# daric register map
Vendor: cramium
Registers are 32-bit, read-write, reset 0x0 unless marked. A register's access mark holds for its fields unless they carry their own. Offsets are from the block's base; [hi:lo] are bit positions; {n}, {i} and the like mark numbered series.

## IOX
Base 0x5012F000
{0x0+4i} SFR_AFSEL_CRAFSEL{i} (i=0..11) — See file:///F:/code/cram-soc/soc_oss/rtl/ifsub/iox_v0.3.sv
  [15:0] crafsel{i} — crafsel read/write control register
{0x100+4i} SFR_INTCR_CRINT{i} (i=0..7) — See file:///F:/code/cram-soc/soc_oss/rtl/ifsub/iox_v0.3.sv
  [9:0] crint{i} — crint read/write control register
0x120 SFR_INTFR — See file:///F:/code/cram-soc/soc_oss/rtl/ifsub/iox_v0.3.sv
  [7:0] frint — frint flag register. `1` means event happened, write back `1` in respective bit position to clear the flag
{0x130+4i} SFR_GPIOOUT_CRGO{i} (i=0..5) — See file:///F:/code/cram-soc/soc_oss/rtl/ifsub/iox_v0.3.sv
  [15:0] crgo{i} — crgo read/write control register
{0x148+4i} SFR_GPIOOE_CRGOE{i} (i=0..5) — See file:///F:/code/cram-soc/soc_oss/rtl/ifsub/iox_v0.3.sv
  [15:0] crgoe{i} — crgoe read/write control register
{0x160+4i} SFR_GPIOPU_CRGPU{i} (i=0..5) — See file:///F:/code/cram-soc/soc_oss/rtl/ifsub/iox_v0.3.sv
  [15:0] crgpu{i} — crgpu read/write control register
{0x178+4i} SFR_GPIOIN_SRGI{i} (i=0..5) — See file:///F:/code/cram-soc/soc_oss/rtl/ifsub/iox_v0.3.sv
  [15:0] srgi{i} — srgi read only status register
0x200 SFR_PIOSEL — See file:///F:/code/cram-soc/soc_oss/rtl/ifsub/iox_v0.3.sv
  [31:0] piosel — piosel read/write control register
{0x230+4i} SFR_CFG_SCHM_CR_CFG_SCHMSEL{i} (i=0..5) — See file:///F:/code/cram-soc/soc_oss/rtl/ifsub/iox_v0.3.sv
  [15:0] cr_cfg_schmsel{i} — cr_cfg_schmsel read/write control register
{0x248+4i} SFR_CFG_SLEW_CR_CFG_SLEWSLOW{i} (i=0..5) — See file:///F:/code/cram-soc/soc_oss/rtl/ifsub/iox_v0.3.sv
  [15:0] cr_cfg_slewslow{i} — cr_cfg_slewslow read/write control register
{0x260+4i} SFR_CFG_DRVSEL_CR_CFG_DRVSEL{i} (i=0..5) — See file:///F:/code/cram-soc/soc_oss/rtl/ifsub/iox_v0.3.sv
  [31:0] cr_cfg_drvsel{i} — cr_cfg_drvsel read/write control register

## CORESUB_SRAMTRM
Base 0x40014000
0x00 SFR_CACHE — See file:///F:/code/cram-soc/soc_oss/rtl/core/coresub_sramtrm_v0.1.sv
  [2:0] sfr_cache — sfr_cache read/write control register
0x04 SFR_ITCM — See file:///F:/code/cram-soc/soc_oss/rtl/core/coresub_sramtrm_v0.1.sv
  [4:0] sfr_itcm — sfr_itcm read/write control register
0x08 SFR_DTCM — See file:///F:/code/cram-soc/soc_oss/rtl/core/coresub_sramtrm_v0.1.sv
  [4:0] sfr_dtcm — sfr_dtcm read/write control register
0x0C SFR_SRAM0 — See file:///F:/code/cram-soc/soc_oss/rtl/core/coresub_sramtrm_v0.1.sv
  [4:0] sfr_sram0 — sfr_sram0 read/write control register
0x10 SFR_SRAM1 — See file:///F:/code/cram-soc/soc_oss/rtl/core/coresub_sramtrm_v0.1.sv
  [4:0] sfr_sram1 — sfr_sram1 read/write control register
0x14 SFR_VEXRAM — See file:///F:/code/cram-soc/soc_oss/rtl/core/coresub_sramtrm_v0.1.sv
  [2:0] sfr_vexram — sfr_vexram read/write control register
0x20 SFR_SRAMERR — See file:///F:/code/cram-soc/soc_oss/rtl/core/coresub_sramtrm_v0.1.sv
  [3:0] srambankerr — srambankerr flag register. `1` means event happened, write back `1` in respective bit position to clear the flag

## MDMA
Base 0x40012000
{0x0+4i} SFR_EVSEL_CR_EVSEL{i} (i=0..7) — See file:///F:/code/cram-soc/soc_oss/rtl/core/mdma_v0.1.sv
  [7:0] cr_evsel{i} — cr_evsel read/write control register
{0x20+4i} SFR_CR_CR_MDMAREQ{i} (i=0..7) — See file:///F:/code/cram-soc/soc_oss/rtl/core/mdma_v0.1.sv
  [4:0] cr_mdmareq{i} — cr_mdmareq read/write control register
{0x40+4i} SFR_SR_SR_MDMAREQ{i} (i=0..7) — See file:///F:/code/cram-soc/soc_oss/rtl/core/mdma_v0.1.sv
  [4:0] sr_mdmareq{i} — sr_mdmareq read only status register

## QFC
Base 0x40010000
0x00 SFR_IO — See file:///F:/code/cram-soc/soc_oss/rtl/core/qfc_v0.2.sv
  [7:0] sfr_io — sfr_io read/write control register
0x04 SFR_AR — See file:///F:/code/cram-soc/soc_oss/rtl/core/qfc_v0.2.sv
  [31:0] sfr_ar — sfr_ar performs action on write of value: 0x5a
0x08 SFR_IODRV — See file:///F:/code/cram-soc/soc_oss/rtl/core/qfc_v0.2.sv
  [11:0] paddrvsel — paddrvsel read/write control register
0x10 CR_XIP_ADDRMODE — See file:///F:/code/cram-soc/soc_oss/rtl/core/qfc_v0.2.sv
  [1:0] cr_xip_addrmode — cr_xip_addrmode read/write control register
0x14 CR_XIP_OPCODE — See file:///F:/code/cram-soc/soc_oss/rtl/core/qfc_v0.2.sv
  [31:0] cr_xip_opcode — cr_xip_opcode read/write control register
0x18 CR_XIP_WIDTH — See file:///F:/code/cram-soc/soc_oss/rtl/core/qfc_v0.2.sv
  [5:0] cr_xip_width — cr_xip_width read/write control register
0x1C CR_XIP_SSEL — See file:///F:/code/cram-soc/soc_oss/rtl/core/qfc_v0.2.sv
  [6:0] cr_xip_ssel — cr_xip_ssel read/write control register
0x20 CR_XIP_DUMCYC — See file:///F:/code/cram-soc/soc_oss/rtl/core/qfc_v0.2.sv
  [15:0] cr_xip_dumcyc — cr_xip_dumcyc read/write control register
0x24 CR_XIP_CFG — See file:///F:/code/cram-soc/soc_oss/rtl/core/qfc_v0.2.sv
  [13:0] cr_xip_cfg — cr_xip_cfg read/write control register
{0x40+4i} CR_AESKEY_AESKEYIN{i} (i=0..3) — See file:///F:/code/cram-soc/soc_oss/rtl/core/qfc_v0.2.sv
  [31:0] aeskeyin{i} — cr_aeskey read/write control register
0x50 CR_AESENA — See file:///F:/code/cram-soc/soc_oss/rtl/core/qfc_v0.2.sv
  [0] cr_aesena — cr_aesena read/write control register

## MBOX_APB
Base 0x40013000
0x00 SFR_WDATA — See file:///F:/code/cram-soc/soc_oss/ips/vexriscv/cram- soc/candidate/mbox_v0.1.sv
  [31:0] sfr_wdata — sfr_wdata read/write control register
0x04 SFR_RDATA — See file:///F:/code/cram-soc/soc_oss/ips/vexriscv/cram- soc/candidate/mbox_v0.1.sv
  [31:0] sfr_rdata — sfr_rdata read only status register
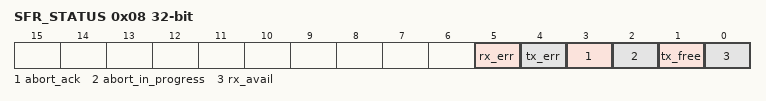
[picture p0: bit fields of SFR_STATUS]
0x08 SFR_STATUS — See file:///F:/code/cram-soc/soc_oss/ips/vexriscv/cram- soc/candidate/mbox_v0.1.sv
  [5] rx_err — rx_err read only status register
  [4] tx_err — tx_err read only status register
  [3] abort_ack — abort_ack read only status register
  [2] abort_in_progress — abort_in_progress read only status register
  [1] tx_free — tx_free read only status register
  [0] rx_avail — rx_avail read only status register
0x18 SFR_ABORT — See file:///F:/code/cram-soc/soc_oss/ips/vexriscv/cram- soc/candidate/mbox_v0.1.sv
  [31:0] sfr_abort — sfr_abort performs action on write of value: 0x1
0x1C SFR_DONE — See file:///F:/code/cram-soc/soc_oss/ips/vexriscv/cram- soc/candidate/mbox_v0.1.sv
  [31:0] sfr_done — sfr_done performs action on write of value: 0x1

## GLUECHAIN
Base 0x40054000
0x00 SFR_GCMASK — See file:///F:/code/cram-soc/soc_oss/rtl/sec/gluechain_v0.1.sv
  [31:0] cr_gcmask — cr_gcmask read/write control register
0x04 SFR_GCSR — See file:///F:/code/cram-soc/soc_oss/rtl/sec/gluechain_v0.1.sv
  [31:0] gluereg — gluereg read only status register
0x08 SFR_GCRST — See file:///F:/code/cram-soc/soc_oss/rtl/sec/gluechain_v0.1.sv
  [31:0] gluerst — gluerst read/write control register
0x0C SFR_GCTEST — See file:///F:/code/cram-soc/soc_oss/rtl/sec/gluechain_v0.1.sv
  [31:0] gluetest — gluetest read/write control register
